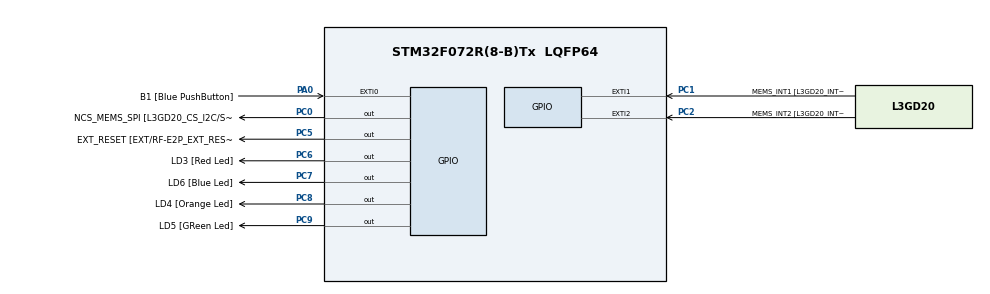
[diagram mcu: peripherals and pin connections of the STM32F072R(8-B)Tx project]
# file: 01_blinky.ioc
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FREERTOS.Tasks01=defaultTask,0,128,StartDefaultTask,Default,NULL
Mcu.Family=STM32F0
Mcu.Name=STM32F072R(8-B)Tx
Mcu.Package=LQFP64
NVIC.TIM1_BRK_UP_TRG_COM_IRQn=true\:0\:0\:false\:false\:true\:false
NVIC.TimeBase=TIM1_BRK_UP_TRG_COM_IRQn
NVIC.TimeBaseIP=TIM1
PA0.GPIO_Label=B1 [Blue PushButton]
PA0.GPIO_ModeDefaultEXTI=GPIO_MODE_EVT_RISING
PA0.Signal=GPXTI0
PA11.GPIO_Label=USBF4_DM
PA11.Signal=USB_DM
PA12.GPIO_Label=USBF4_DP
PA12.Signal=USB_DP
PA13.GPIO_Label=SWDIO
PA13.Signal=SYS_SWDIO
PA14.GPIO_Label=SWCLK
PA14.Signal=SYS_SWCLK
PA2.Signal=TSC_G1_IO3
PA3.Signal=TSC_G1_IO4
PA6.Signal=TSC_G2_IO3
PA7.Signal=TSC_G2_IO4
PB0.Signal=TSC_G3_IO2
PB1.Signal=TSC_G3_IO3
PB10.GPIO_Label=I2C2_SCL[EXT/RF-E2P_SCL]
PB10.Signal=I2C2_SCL
PB11.GPIO_Label=I2C2_SDA[EXT/RF-E2P_SDA]
PB11.Signal=I2C2_SDA
PB13.GPIO_Label=SPI2_SCK [L3GD20_SCL/SPC]
PB13.Signal=SPI2_SCK
PB14.GPIO_Label=SPI2_MISO [L3GD20_SDO]
PB14.Signal=SPI2_MISO
PB15.GPIO_Label=SPI2_MOSI [L3GD20_SDA/SDI]
PB15.Signal=SPI2_MOSI
PC0.GPIO_Label=NCS_MEMS_SPI [L3GD20_CS_I2C/SPI]
PC0.Signal=GPIO_Output
PC1.GPIO_Label=MEMS_INT1 [L3GD20_INT1]
PC1.GPIO_ModeDefaultEXTI=GPIO_MODE_EVT_RISING
PC1.Signal=GPXTI1
PC2.GPIO_Label=MEMS_INT2 [L3GD20_INT2]
PC2.GPIO_ModeDefaultEXTI=GPIO_MODE_EVT_RISING
PC2.Signal=GPXTI2
PC5.GPIO_Label=EXT_RESET [EXT/RF-E2P_EXT_RESET]
PC5.Signal=GPIO_Output
PC6.GPIO_Label=LD3 [Red Led]
PC6.Signal=GPIO_Output
PC7.GPIO_Label=LD6 [Blue Led]
PC7.Signal=GPIO_Output
PC8.GPIO_Label=LD4 [Orange Led]
PC8.Signal=GPIO_Output
PC9.GPIO_Label=LD5 [GReen Led]
PC9.Signal=GPIO_Output
ProjectManager.HeapSize=0x200
ProjectManager.StackSize=0x400
ProjectManager.TargetToolchain=MDK-ARM V5
RCC.AHBFreq_Value=48000000
RCC.APB1Freq_Value=48000000
RCC.APB1TimFreq_Value=48000000
RCC.HCLKFreq_Value=48000000
RCC.PLLMUL=RCC_PLL_MUL6
RCC.SYSCLKFreq_VALUE=48000000
RCC.SYSCLKSource=RCC_SYSCLKSOURCE_PLLCLK
VP_FREERTOS_VS_ENABLE.Mode=Enabled
VP_SYS_VS_tim1.Mode=TIM1
board=STM32F072B-DISCO

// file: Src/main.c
/**
  ******************************************************************************
  * File Name          : main.c
  * Description        : Main program body
  ******************************************************************************
  * This notice applies to any and all portions of this file
  * that are not between comment pairs USER CODE BEGIN and
  * USER CODE END. Other portions of this file, whether
  * inserted by the user or by software development tools
  * are owned by their respective copyright owners.
  *
  * Copyright (c) 2017 STMicroelectronics International N.V.
  * All rights reserved.
  *
  * Redistribution and use in source and binary forms, with or without
  * modification, are permitted, provided that the following conditions are met:
  *
  * 1. Redistribution of source code must retain the above copyright notice,
  *    this list of conditions and the following disclaimer.
  * 2. Redistributions in binary form must reproduce the above copyright notice,
  *    this list of conditions and the following disclaimer in the documentation
  *    and/or other materials provided with the distribution.
  * 3. Neither the name of STMicroelectronics nor the names of other
  *    contributors to this software may be used to endorse or promote products
  *    derived from this software without specific written permission.
  * 4. This software, including modifications and/or derivative works of this
  *    software, must execute solely and exclusively on microcontroller or
  *    microprocessor devices manufactured by or for STMicroelectronics.
  * 5. Redistribution and use of this software other than as permitted under
  *    this license is void and will automatically terminate your rights under
  *    this license.
  *
  * THIS SOFTWARE IS PROVIDED BY STMICROELECTRONICS AND CONTRIBUTORS "AS IS"
  * AND ANY EXPRESS, IMPLIED OR STATUTORY WARRANTIES, INCLUDING, BUT NOT
  * LIMITED TO, THE IMPLIED WARRANTIES OF MERCHANTABILITY, FITNESS FOR A
  * PARTICULAR PURPOSE AND NON-INFRINGEMENT OF THIRD PARTY INTELLECTUAL PROPERTY
  * RIGHTS ARE DISCLAIMED TO THE FULLEST EXTENT PERMITTED BY LAW. IN NO EVENT
  * SHALL STMICROELECTRONICS OR CONTRIBUTORS BE LIABLE FOR ANY DIRECT, INDIRECT,
  * INCIDENTAL, SPECIAL, EXEMPLARY, OR CONSEQUENTIAL DAMAGES (INCLUDING, BUT NOT
  * LIMITED TO, PROCUREMENT OF SUBSTITUTE GOODS OR SERVICES; LOSS OF USE, DATA,
  * OR PROFITS; OR BUSINESS INTERRUPTION) HOWEVER CAUSED AND ON ANY THEORY OF
  * LIABILITY, WHETHER IN CONTRACT, STRICT LIABILITY, OR TORT (INCLUDING
  * NEGLIGENCE OR OTHERWISE) ARISING IN ANY WAY OUT OF THE USE OF THIS SOFTWARE,
  * EVEN IF ADVISED OF THE POSSIBILITY OF SUCH DAMAGE.
  *
  ******************************************************************************
  */
#include "main.h"
#include "stm32f0xx_hal.h"
#include "cmsis_os.h"

osThreadId defaultTaskHandle;
volatile uint16_t blinkSpeed = 1000;

/* USER CODE BEGIN PV */
/* Private variables ---------------------------------------------------------*/

/* USER CODE END PV */

void SystemClock_Config(void);
static void MX_GPIO_Init(void);
void StartDefaultTask(void const * argument);

/* USER CODE BEGIN PFP */
/* Private function prototypes -----------------------------------------------*/

/* USER CODE END PFP */

int main(void)
{

  /* MCU Configuration----------------------------------------------------------*/

  /* Reset of all peripherals, Initializes the Flash interface and the Systick. */
  HAL_Init();

  /* Configure the system clock */
  SystemClock_Config();

  /* Initialize all configured peripherals */
  MX_GPIO_Init();

  /* Create the thread(s) */
  /* definition and creation of defaultTask */
  osThreadDef(defaultTask, StartDefaultTask, osPriorityNormal, 0, 128);
  defaultTaskHandle = osThreadCreate(osThread(defaultTask), NULL);

  /* Start scheduler */
  osKernelStart();

  /* We should never get here as control is now taken by the scheduler */

  /* Infinite loop */
  while (1)
  {

  }

}

/** System Clock Configuration
*/
void SystemClock_Config(void)
{

  LL_FLASH_SetLatency(LL_FLASH_LATENCY_1);

  if(LL_FLASH_GetLatency() != LL_FLASH_LATENCY_1)
  {
  Error_Handler();
  }
  LL_RCC_HSI_Enable();

   /* Wait till HSI is ready */
  while(LL_RCC_HSI_IsReady() != 1)
  {

  }
  LL_RCC_HSI_SetCalibTrimming(16);

  LL_RCC_PLL_ConfigDomain_SYS(LL_RCC_PLLSOURCE_HSI, LL_RCC_PLL_MUL_6, LL_RCC_PREDIV_DIV_1);

  LL_RCC_PLL_Enable();

   /* Wait till PLL is ready */
  while(LL_RCC_PLL_IsReady() != 1)
  {

  }
  LL_RCC_SetAHBPrescaler(LL_RCC_SYSCLK_DIV_1);

  LL_RCC_SetAPB1Prescaler(LL_RCC_APB1_DIV_1);

  LL_RCC_SetSysClkSource(LL_RCC_SYS_CLKSOURCE_PLL);

   /* Wait till System clock is ready */
  while(LL_RCC_GetSysClkSource() != LL_RCC_SYS_CLKSOURCE_STATUS_PLL)
  {

  }
  LL_Init1msTick(48000000);

  LL_SYSTICK_SetClkSource(LL_SYSTICK_CLKSOURCE_HCLK);

  LL_SetSystemCoreClock(48000000);

  /* SysTick_IRQn interrupt configuration */
  NVIC_SetPriority(SysTick_IRQn, 3);
}

/** Configure pins as
        * Analog
        * Input
        * Output
        * EVENT_OUT
        * EXTI
     PA2   ------> TSC_G1_IO3
     PA3   ------> TSC_G1_IO4
     PA6   ------> TSC_G2_IO3
     PA7   ------> TSC_G2_IO4
     PB0   ------> TSC_G3_IO2
     PB1   ------> TSC_G3_IO3
     PB10   ------> I2C2_SCL
     PB11   ------> I2C2_SDA
     PB13   ------> SPI2_SCK
     PB14   ------> SPI2_MISO
     PB15   ------> SPI2_MOSI
*/
static void MX_GPIO_Init(void)
{

  LL_GPIO_InitTypeDef GPIO_InitStruct;
  LL_EXTI_InitTypeDef EXTI_InitStruct;

  /* GPIO Ports Clock Enable */
  LL_AHB1_GRP1_EnableClock(LL_AHB1_GRP1_PERIPH_GPIOC);
  LL_AHB1_GRP1_EnableClock(LL_AHB1_GRP1_PERIPH_GPIOA);
  LL_AHB1_GRP1_EnableClock(LL_AHB1_GRP1_PERIPH_GPIOB);

  /**/
  LL_GPIO_ResetOutputPin(NCS_MEMS_SPI_GPIO_Port, NCS_MEMS_SPI_Pin);

  /**/
  LL_GPIO_ResetOutputPin(EXT_RESET_GPIO_Port, EXT_RESET_Pin);

  /**/
  LL_GPIO_ResetOutputPin(LD3_GPIO_Port, LD3_Pin);

  /**/
  LL_GPIO_ResetOutputPin(LD6_GPIO_Port, LD6_Pin);

  /**/
  LL_GPIO_ResetOutputPin(LD4_GPIO_Port, LD4_Pin);

  /**/
  LL_GPIO_ResetOutputPin(LD5_GPIO_Port, LD5_Pin);

  /**/
  GPIO_InitStruct.Pin = NCS_MEMS_SPI_Pin;
  GPIO_InitStruct.Mode = LL_GPIO_MODE_OUTPUT;
  GPIO_InitStruct.Speed = LL_GPIO_SPEED_FREQ_LOW;
  GPIO_InitStruct.OutputType = LL_GPIO_OUTPUT_PUSHPULL;
  GPIO_InitStruct.Pull = LL_GPIO_PULL_NO;
  LL_GPIO_Init(NCS_MEMS_SPI_GPIO_Port, &GPIO_InitStruct);

  /**/
  GPIO_InitStruct.Pin = LL_GPIO_PIN_2;
  GPIO_InitStruct.Mode = LL_GPIO_MODE_ALTERNATE;
  GPIO_InitStruct.Speed = LL_GPIO_SPEED_FREQ_LOW;
  GPIO_InitStruct.OutputType = LL_GPIO_OUTPUT_PUSHPULL;
  GPIO_InitStruct.Pull = LL_GPIO_PULL_NO;
  GPIO_InitStruct.Alternate = LL_GPIO_AF_3;
  LL_GPIO_Init(GPIOA, &GPIO_InitStruct);

  /**/
  GPIO_InitStruct.Pin = LL_GPIO_PIN_3;
  GPIO_InitStruct.Mode = LL_GPIO_MODE_ALTERNATE;
  GPIO_InitStruct.Speed = LL_GPIO_SPEED_FREQ_LOW;
  GPIO_InitStruct.OutputType = LL_GPIO_OUTPUT_PUSHPULL;
  GPIO_InitStruct.Pull = LL_GPIO_PULL_NO;
  GPIO_InitStruct.Alternate = LL_GPIO_AF_3;
  LL_GPIO_Init(GPIOA, &GPIO_InitStruct);

  /**/
  GPIO_InitStruct.Pin = LL_GPIO_PIN_6;
  GPIO_InitStruct.Mode = LL_GPIO_MODE_ALTERNATE;
  GPIO_InitStruct.Speed = LL_GPIO_SPEED_FREQ_LOW;
  GPIO_InitStruct.OutputType = LL_GPIO_OUTPUT_PUSHPULL;
  GPIO_InitStruct.Pull = LL_GPIO_PULL_NO;
  GPIO_InitStruct.Alternate = LL_GPIO_AF_3;
  LL_GPIO_Init(GPIOA, &GPIO_InitStruct);

  /**/
  GPIO_InitStruct.Pin = LL_GPIO_PIN_7;
  GPIO_InitStruct.Mode = LL_GPIO_MODE_ALTERNATE;
  GPIO_InitStruct.Speed = LL_GPIO_SPEED_FREQ_LOW;
  GPIO_InitStruct.OutputType = LL_GPIO_OUTPUT_PUSHPULL;
  GPIO_InitStruct.Pull = LL_GPIO_PULL_NO;
  GPIO_InitStruct.Alternate = LL_GPIO_AF_3;
  LL_GPIO_Init(GPIOA, &GPIO_InitStruct);

  /**/
  GPIO_InitStruct.Pin = EXT_RESET_Pin;
  GPIO_InitStruct.Mode = LL_GPIO_MODE_OUTPUT;
  GPIO_InitStruct.Speed = LL_GPIO_SPEED_FREQ_LOW;
  GPIO_InitStruct.OutputType = LL_GPIO_OUTPUT_PUSHPULL;
  GPIO_InitStruct.Pull = LL_GPIO_PULL_NO;
  LL_GPIO_Init(EXT_RESET_GPIO_Port, &GPIO_InitStruct);

  /**/
  GPIO_InitStruct.Pin = LL_GPIO_PIN_0;
  GPIO_InitStruct.Mode = LL_GPIO_MODE_ALTERNATE;
  GPIO_InitStruct.Speed = LL_GPIO_SPEED_FREQ_LOW;
  GPIO_InitStruct.OutputType = LL_GPIO_OUTPUT_PUSHPULL;
  GPIO_InitStruct.Pull = LL_GPIO_PULL_NO;
  GPIO_InitStruct.Alternate = LL_GPIO_AF_3;
  LL_GPIO_Init(GPIOB, &GPIO_InitStruct);

  /**/
  GPIO_InitStruct.Pin = LL_GPIO_PIN_1;
  GPIO_InitStruct.Mode = LL_GPIO_MODE_ALTERNATE;
  GPIO_InitStruct.Speed = LL_GPIO_SPEED_FREQ_LOW;
  GPIO_InitStruct.OutputType = LL_GPIO_OUTPUT_PUSHPULL;
  GPIO_InitStruct.Pull = LL_GPIO_PULL_NO;
  GPIO_InitStruct.Alternate = LL_GPIO_AF_3;
  LL_GPIO_Init(GPIOB, &GPIO_InitStruct);

  /**/
  GPIO_InitStruct.Pin = I2C2_SCL_Pin;
  GPIO_InitStruct.Mode = LL_GPIO_MODE_ALTERNATE;
  GPIO_InitStruct.Speed = LL_GPIO_SPEED_FREQ_HIGH;
  GPIO_InitStruct.OutputType = LL_GPIO_OUTPUT_OPENDRAIN;
  GPIO_InitStruct.Pull = LL_GPIO_PULL_UP;
  GPIO_InitStruct.Alternate = LL_GPIO_AF_1;
  LL_GPIO_Init(I2C2_SCL_GPIO_Port, &GPIO_InitStruct);

  /**/
  GPIO_InitStruct.Pin = I2C2_SDA_Pin;
  GPIO_InitStruct.Mode = LL_GPIO_MODE_ALTERNATE;
  GPIO_InitStruct.Speed = LL_GPIO_SPEED_FREQ_HIGH;
  GPIO_InitStruct.OutputType = LL_GPIO_OUTPUT_OPENDRAIN;
  GPIO_InitStruct.Pull = LL_GPIO_PULL_UP;
  GPIO_InitStruct.Alternate = LL_GPIO_AF_1;
  LL_GPIO_Init(I2C2_SDA_GPIO_Port, &GPIO_InitStruct);

  /**/
  GPIO_InitStruct.Pin = SPI2_SCK_Pin;
  GPIO_InitStruct.Mode = LL_GPIO_MODE_ALTERNATE;
  GPIO_InitStruct.Speed = LL_GPIO_SPEED_FREQ_HIGH;
  GPIO_InitStruct.OutputType = LL_GPIO_OUTPUT_PUSHPULL;
  GPIO_InitStruct.Pull = LL_GPIO_PULL_NO;
  GPIO_InitStruct.Alternate = LL_GPIO_AF_0;
  LL_GPIO_Init(SPI2_SCK_GPIO_Port, &GPIO_InitStruct);

  /**/
  GPIO_InitStruct.Pin = SPI2_MISO_Pin;
  GPIO_InitStruct.Mode = LL_GPIO_MODE_ALTERNATE;
  GPIO_InitStruct.Speed = LL_GPIO_SPEED_FREQ_HIGH;
  GPIO_InitStruct.OutputType = LL_GPIO_OUTPUT_PUSHPULL;
  GPIO_InitStruct.Pull = LL_GPIO_PULL_NO;
  GPIO_InitStruct.Alternate = LL_GPIO_AF_0;
  LL_GPIO_Init(SPI2_MISO_GPIO_Port, &GPIO_InitStruct);

  /**/
  GPIO_InitStruct.Pin = SPI2_MOSI_Pin;
  GPIO_InitStruct.Mode = LL_GPIO_MODE_ALTERNATE;
  GPIO_InitStruct.Speed = LL_GPIO_SPEED_FREQ_HIGH;
  GPIO_InitStruct.OutputType = LL_GPIO_OUTPUT_PUSHPULL;
  GPIO_InitStruct.Pull = LL_GPIO_PULL_NO;
  GPIO_InitStruct.Alternate = LL_GPIO_AF_0;
  LL_GPIO_Init(SPI2_MOSI_GPIO_Port, &GPIO_InitStruct);

  /**/
  GPIO_InitStruct.Pin = LD3_Pin;
  GPIO_InitStruct.Mode = LL_GPIO_MODE_OUTPUT;
  GPIO_InitStruct.Speed = LL_GPIO_SPEED_FREQ_LOW;
  GPIO_InitStruct.OutputType = LL_GPIO_OUTPUT_PUSHPULL;
  GPIO_InitStruct.Pull = LL_GPIO_PULL_NO;
  LL_GPIO_Init(LD3_GPIO_Port, &GPIO_InitStruct);

  /**/
  GPIO_InitStruct.Pin = LD6_Pin;
  GPIO_InitStruct.Mode = LL_GPIO_MODE_OUTPUT;
  GPIO_InitStruct.Speed = LL_GPIO_SPEED_FREQ_LOW;
  GPIO_InitStruct.OutputType = LL_GPIO_OUTPUT_PUSHPULL;
  GPIO_InitStruct.Pull = LL_GPIO_PULL_NO;
  LL_GPIO_Init(LD6_GPIO_Port, &GPIO_InitStruct);

  /**/
  GPIO_InitStruct.Pin = LD4_Pin;
  GPIO_InitStruct.Mode = LL_GPIO_MODE_OUTPUT;
  GPIO_InitStruct.Speed = LL_GPIO_SPEED_FREQ_LOW;
  GPIO_InitStruct.OutputType = LL_GPIO_OUTPUT_PUSHPULL;
  GPIO_InitStruct.Pull = LL_GPIO_PULL_NO;
  LL_GPIO_Init(LD4_GPIO_Port, &GPIO_InitStruct);

  /**/
  GPIO_InitStruct.Pin = LD5_Pin;
  GPIO_InitStruct.Mode = LL_GPIO_MODE_OUTPUT;
  GPIO_InitStruct.Speed = LL_GPIO_SPEED_FREQ_LOW;
  GPIO_InitStruct.OutputType = LL_GPIO_OUTPUT_PUSHPULL;
  GPIO_InitStruct.Pull = LL_GPIO_PULL_NO;
  LL_GPIO_Init(LD5_GPIO_Port, &GPIO_InitStruct);

  /**/
  LL_SYSCFG_SetEXTISource(LL_SYSCFG_EXTI_PORTC, LL_SYSCFG_EXTI_LINE1);

  /**/
  LL_SYSCFG_SetEXTISource(LL_SYSCFG_EXTI_PORTC, LL_SYSCFG_EXTI_LINE2);

  /**/
  LL_SYSCFG_SetEXTISource(LL_SYSCFG_EXTI_PORTA, LL_SYSCFG_EXTI_LINE0);

  /**/
  LL_GPIO_SetPinPull(MEMS_INT1_GPIO_Port, MEMS_INT1_Pin, LL_GPIO_PULL_NO);

  /**/
  LL_GPIO_SetPinPull(MEMS_INT2_GPIO_Port, MEMS_INT2_Pin, LL_GPIO_PULL_NO);

  /**/
  LL_GPIO_SetPinPull(GPIOA, LL_GPIO_PIN_0, LL_GPIO_PULL_NO);

  /**/
  LL_GPIO_SetPinMode(MEMS_INT1_GPIO_Port, MEMS_INT1_Pin, LL_GPIO_MODE_INPUT);

  /**/
  LL_GPIO_SetPinMode(MEMS_INT2_GPIO_Port, MEMS_INT2_Pin, LL_GPIO_MODE_INPUT);

  /**/
  LL_GPIO_SetPinMode(GPIOA, LL_GPIO_PIN_0, LL_GPIO_MODE_INPUT);

  /**/
  EXTI_InitStruct.Line_0_31 = LL_EXTI_LINE_1;
  EXTI_InitStruct.LineCommand = ENABLE;
  EXTI_InitStruct.Mode = LL_EXTI_MODE_EVENT;
  EXTI_InitStruct.Trigger = LL_EXTI_TRIGGER_RISING;
  LL_EXTI_Init(&EXTI_InitStruct);

  /**/
  EXTI_InitStruct.Line_0_31 = LL_EXTI_LINE_2;
  EXTI_InitStruct.LineCommand = ENABLE;
  EXTI_InitStruct.Mode = LL_EXTI_MODE_EVENT;
  EXTI_InitStruct.Trigger = LL_EXTI_TRIGGER_RISING;
  LL_EXTI_Init(&EXTI_InitStruct);

  /**/
  EXTI_InitStruct.Line_0_31 = LL_EXTI_LINE_0;
  EXTI_InitStruct.LineCommand = ENABLE;
  EXTI_InitStruct.Mode = LL_EXTI_MODE_IT;
  EXTI_InitStruct.Trigger = LL_EXTI_TRIGGER_RISING;
  LL_EXTI_Init(&EXTI_InitStruct);

  /* EXTI interrupt init*/
  NVIC_SetPriority(EXTI0_1_IRQn, 3);
  NVIC_EnableIRQ(EXTI0_1_IRQn);

}

/* StartDefaultTask function */
void StartDefaultTask(void const * argument)
{

  /* USER CODE BEGIN 5 */
  NVIC_EnableIRQ(EXTI0_1_IRQn);
  LL_GPIO_SetOutputPin(LD3_GPIO_Port, LD3_Pin);
  LL_GPIO_SetOutputPin(LD6_GPIO_Port, LD6_Pin);
  /* Infinite loop */
  for(;;)
  {
    LL_GPIO_TogglePin(LD3_GPIO_Port, LD3_Pin);
    LL_GPIO_TogglePin(LD4_GPIO_Port, LD4_Pin);
    LL_GPIO_TogglePin(LD5_GPIO_Port, LD5_Pin);
    LL_GPIO_TogglePin(LD6_GPIO_Port, LD6_Pin);
    LL_mDelay(blinkSpeed);
    //osDelay(1);
  }
  /* USER CODE END 5 */
}

void HAL_TIM_PeriodElapsedCallback(TIM_HandleTypeDef *htim)
{
  if (htim->Instance == TIM1) {
    HAL_IncTick();
  }
}

void _Error_Handler(char * file, int line)
{
  while(1)
  {
  }
}

/************************ (C) COPYRIGHT STMicroelectronics *****END OF FILE****/
